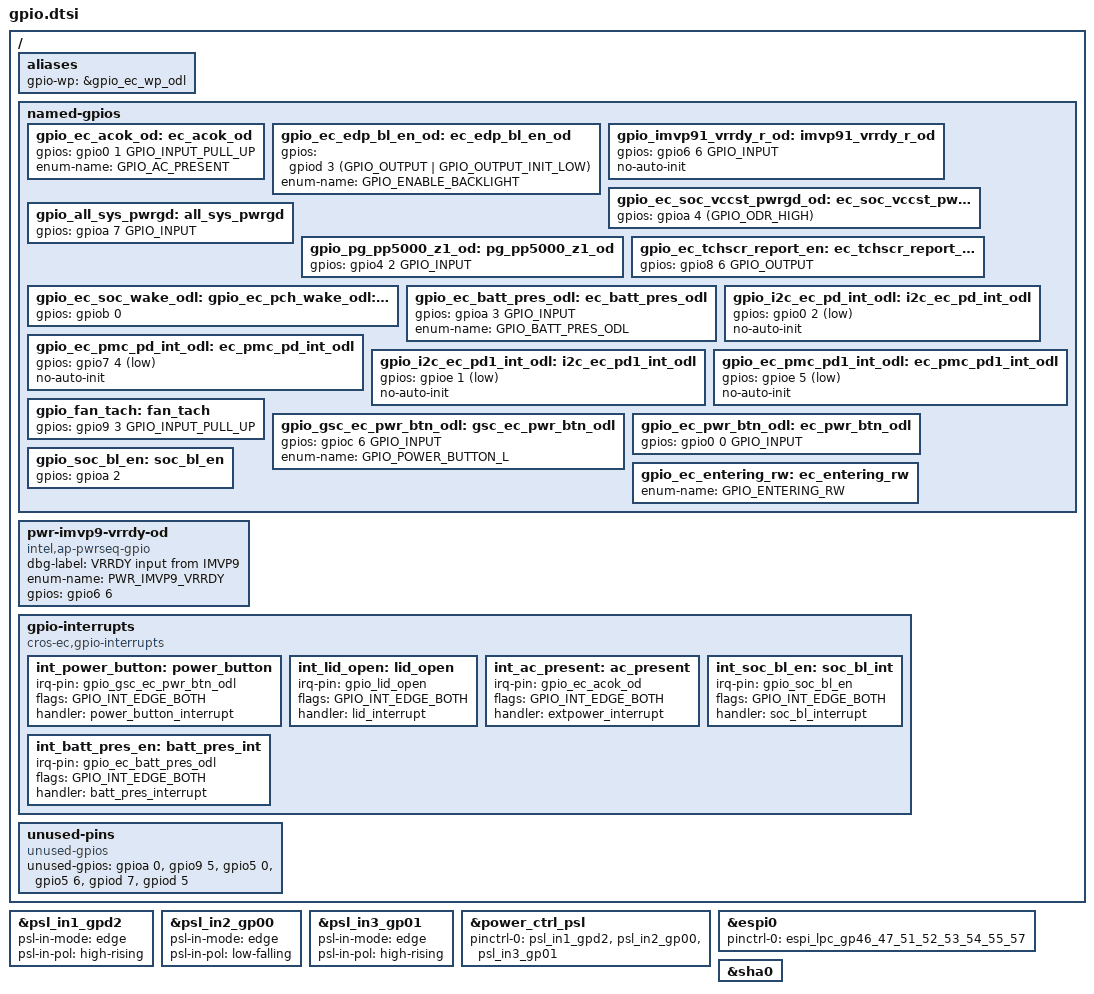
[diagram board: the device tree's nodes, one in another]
/* Copyright 2025 The ChromiumOS Authors
 * Use of this source code is governed by a BSD-style license that can be
 * found in the LICENSE file.
 */

 #include <cros/integrated_fwid.dtsi>

 / {

	aliases {
		gpio-wp = &gpio_ec_wp_odl;
	};

	named-gpios {
		/delete-node/ acok_od;
		/delete-node/ ec_edp_bl_en_od;
		/delete-node/ imvp91_vrrdy_r_od;
		/delete-node/ ec_soc_vccst_pwrgd_od;
		/delete-node/ all_sys_pwrgd;
		/delete-node/ pg_pp5000_z1_od;
		/delete-node/ ccd_mode_odl;
		/delete-node/ ec_soc_wake_odl;
		/delete-node/ en_kb_bl;
		/delete-node/ i2c_ec_pd_int_odl;
		/delete-node/ ec_pmc_pd_int_odl;
		/delete-node/ volup_btn_odl;
		/delete-node/ voldn_btn_odl;
		/delete-node/ acc_int_l;
		/delete-node/ imu_int_l;
		/delete-node/ tablet_mode_l;
		/delete-node/ gsc_ec_pwr_btn_odl;
		/delete-node/ ec_pwr_btn_odl;
		/delete-node/ ec_tris_l;
		/delete-node/ en_z1_rails;

		gpio_ec_acok_od: ec_acok_od {
			gpios = <&gpio0 1 GPIO_INPUT_PULL_UP>;
			enum-name = "GPIO_AC_PRESENT";
		};
		gpio_ec_edp_bl_en_od: ec_edp_bl_en_od {
			gpios = <&gpiod 3 (GPIO_OUTPUT | GPIO_OUTPUT_INIT_LOW)>;
			enum-name = "GPIO_ENABLE_BACKLIGHT";
		};
		gpio_imvp91_vrrdy_r_od: imvp91_vrrdy_r_od {
			gpios = <&gpio6 6 GPIO_INPUT>;
			no-auto-init;
		};
		gpio_ec_soc_vccst_pwrgd_od: ec_soc_vccst_pwrgd_od {
			gpios = <&gpioa 4 (GPIO_ODR_HIGH)>;
		};
		gpio_all_sys_pwrgd: all_sys_pwrgd {
			gpios = <&gpioa 7 GPIO_INPUT>;
		};
		gpio_pg_pp5000_z1_od: pg_pp5000_z1_od {
			gpios = <&gpio4 2 GPIO_INPUT>;
		};
		gpio_ec_tchscr_report_en: ec_tchscr_report_en {
			gpios = <&gpio8 6 GPIO_OUTPUT>;
		};
		gpio_ec_soc_wake_odl: ec_soc_wake_odl {
			gpios = <&gpiob 0 (GPIO_OUTPUT | GPIO_OPEN_DRAIN | GPIO_OUTPUT_INIT_LOW)>;
		};
		gpio_ec_batt_pres_odl: ec_batt_pres_odl {
			gpios = <&gpioa 3 GPIO_INPUT>;
			enum-name = "GPIO_BATT_PRES_ODL";
		};
		gpio_i2c_ec_pd_int_odl: i2c_ec_pd_int_odl {
			gpios = <&gpio0 2 (GPIO_INPUT | GPIO_ACTIVE_LOW)>;
		};
		gpio_ec_pmc_pd_int_odl: ec_pmc_pd_int_odl {
			gpios = <&gpio7 4 (GPIO_INPUT | GPIO_ACTIVE_LOW)>;
		};
		gpio_i2c_ec_pd1_int_odl: i2c_ec_pd1_int_odl {
			gpios = <&gpioe 1 (GPIO_INPUT | GPIO_ACTIVE_LOW)>;
		};
		gpio_ec_pmc_pd1_int_odl: ec_pmc_pd1_int_odl {
			gpios = <&gpioe 5 (GPIO_INPUT | GPIO_ACTIVE_LOW)>;
		};
		gpio_fan_tach: fan_tach {
			gpios = <&gpio9 3 GPIO_INPUT_PULL_UP>;
		};
		gpio_gsc_ec_pwr_btn_odl: gsc_ec_pwr_btn_odl {
			gpios = <&gpioc 6 GPIO_INPUT>;
			enum-name = "GPIO_POWER_BUTTON_L";
		};
		gpio_ec_pwr_btn_odl: ec_pwr_btn_odl {
			gpios = <&gpio0 0 GPIO_INPUT>;
		};
		/* The legacy system code requires GPIO_ENTERING_RW symbol */
		gpio_ec_entering_rw: ec_entering_rw {
			enum-name = "GPIO_ENTERING_RW";
		};
		gpio_soc_bl_en: soc_bl_en {
			gpios = <&gpioa 2 (GPIO_INPUT | GPIO_PULL_UP)>;
		};
	};

	pwr-imvp9-vrrdy-od {
		compatible = "intel,ap-pwrseq-gpio";
		dbg-label = "VRRDY input from IMVP9";
		enum-name = "PWR_IMVP9_VRRDY";
		gpios = <&gpio6 6 0>;
	};

	gpio-interrupts {
		compatible = "cros-ec,gpio-interrupts";

		int_power_button: power_button {
			irq-pin = <&gpio_gsc_ec_pwr_btn_odl>;
			flags = <GPIO_INT_EDGE_BOTH>;
			handler = "power_button_interrupt";
		};
		int_lid_open: lid_open {
			irq-pin = <&gpio_lid_open>;
			flags = <GPIO_INT_EDGE_BOTH>;
			handler = "lid_interrupt";
		};
		int_ac_present: ac_present {
			irq-pin = <&gpio_ec_acok_od>;
			flags = <GPIO_INT_EDGE_BOTH>;
			handler = "extpower_interrupt";
		};
		int_soc_bl_en: soc_bl_int{
			irq-pin = <&gpio_soc_bl_en>;
			flags = <GPIO_INT_EDGE_BOTH>;
			handler = "soc_bl_interrupt";
		};
		int_batt_pres_en: batt_pres_int{
			irq-pin = <&gpio_ec_batt_pres_odl>;
			flags = <GPIO_INT_EDGE_BOTH>;
			handler = "batt_pres_interrupt";
		};
	};

	unused-pins {
		compatible = "unused-gpios";
		unused-gpios =
			<&gpioa 0 0>,
			<&gpio9 5 0>,
			<&gpio5 0 0>,
			<&gpio5 6 0>,
			<&gpiod 7 0>,
			<&gpiod 5 0>;
	};
};

/* These GPIOS are initialized by the PDC driver */
&gpio_i2c_ec_pd_int_odl {
	no-auto-init;
};
&gpio_ec_pmc_pd_int_odl {
	no-auto-init;
};
&gpio_i2c_ec_pd1_int_odl {
	no-auto-init;
};
&gpio_ec_pmc_pd1_int_odl {
	no-auto-init;
};

/* Power switch logic input pads */
/* LID_OPEN_OD */
&psl_in1_gpd2 {
	psl-in-mode = "edge";
	psl-in-pol = "high-rising";
};

/* EC_PWR_BTN_ODL */
&psl_in2_gp00 {
	psl-in-mode = "edge";
	psl-in-pol = "low-falling";
};

/* ACOK_EC_OD */
&psl_in3_gp01 {
	psl-in-mode = "edge";
	psl-in-pol = "high-rising";
};

/* Power domain device controlled by PSL (Power Switch Logic) IO pads */
&power_ctrl_psl {
	status = "okay";
	pinctrl-names = "sleep";
	pinctrl-0 = <&psl_in1_gpd2 &psl_in2_gp00 &psl_in3_gp01>;
};

/* The eSPI shim requires this GPIO nodelabel */
gpio_ec_pch_wake_odl: &gpio_ec_soc_wake_odl {
};

/* host interface */
&espi0 {
	status = "okay";
	pinctrl-0 = <&espi_lpc_gp46_47_51_52_53_54_55_57>;
	pinctrl-names = "default";
};

&sha0 {
	status = "okay";
};
